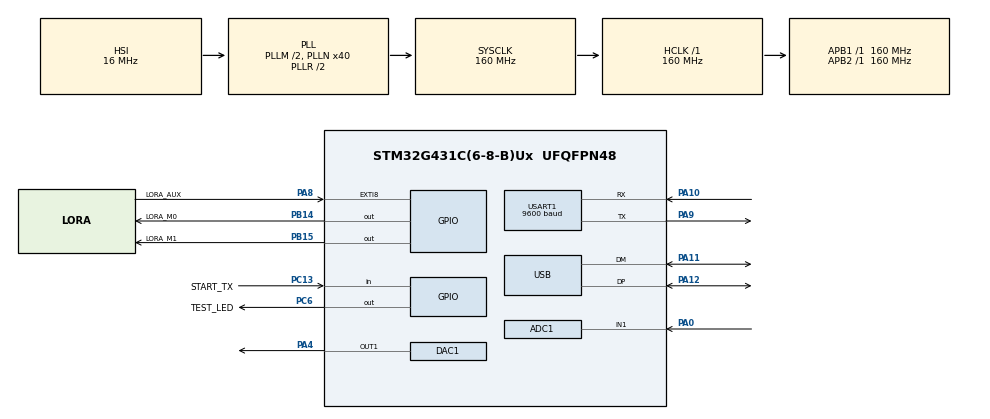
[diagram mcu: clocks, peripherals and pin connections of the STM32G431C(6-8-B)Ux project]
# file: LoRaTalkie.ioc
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ADC1.Channel-0\#ChannelRegularConversion=ADC_CHANNEL_1
ADC1.ClockPrescaler=ADC_CLOCK_SYNC_PCLK_DIV4
ADC1.ContinuousConvMode=DISABLE
ADC1.DMAContinuousRequests=ENABLE
ADC1.ExternalTrigConv=ADC_EXTERNALTRIG_T2_TRGO
ADC1.NbrOfConversionFlag=1
ADC1.OffsetNumber-0\#ChannelRegularConversion=ADC_OFFSET_NONE
ADC1.Overrun=ADC_OVR_DATA_OVERWRITTEN
ADC1.Rank-0\#ChannelRegularConversion=1
ADC1.Resolution=ADC_RESOLUTION_8B
ADC1.SamplingTime-0\#ChannelRegularConversion=ADC_SAMPLETIME_2CYCLES_5
ADC1.master=1
DAC1.DAC_Trigger_OUT1-DAC_OUT1=DAC_TRIGGER_T2_TRGO
DAC1.WaveGeneration_OUT1-DAC_OUT1=DISABLE
Dma.ADC1.0.Direction=DMA_PERIPH_TO_MEMORY
Dma.ADC1.0.EventEnable=DISABLE
Dma.ADC1.0.Instance=DMA1_Channel1
Dma.ADC1.0.MemDataAlignment=DMA_MDATAALIGN_HALFWORD
Dma.ADC1.0.MemInc=DMA_MINC_ENABLE
Dma.ADC1.0.Mode=DMA_CIRCULAR
Dma.ADC1.0.PeriphDataAlignment=DMA_PDATAALIGN_HALFWORD
Dma.ADC1.0.PeriphInc=DMA_PINC_DISABLE
Dma.ADC1.0.Polarity=HAL_DMAMUX_REQ_GEN_RISING
Dma.ADC1.0.Priority=DMA_PRIORITY_LOW
Dma.ADC1.0.RequestNumber=1
Dma.ADC1.0.SignalID=NONE
Dma.ADC1.0.SyncEnable=DISABLE
Dma.ADC1.0.SyncPolarity=HAL_DMAMUX_SYNC_NO_EVENT
Dma.ADC1.0.SyncRequestNumber=1
Dma.ADC1.0.SyncSignalID=NONE
Dma.DAC1_CH1.1.Direction=DMA_MEMORY_TO_PERIPH
Dma.DAC1_CH1.1.EventEnable=DISABLE
Dma.DAC1_CH1.1.Instance=DMA1_Channel2
Dma.DAC1_CH1.1.MemDataAlignment=DMA_MDATAALIGN_HALFWORD
Dma.DAC1_CH1.1.MemInc=DMA_MINC_ENABLE
Dma.DAC1_CH1.1.Mode=DMA_CIRCULAR
Dma.DAC1_CH1.1.PeriphDataAlignment=DMA_PDATAALIGN_WORD
Dma.DAC1_CH1.1.PeriphInc=DMA_PINC_DISABLE
Dma.DAC1_CH1.1.Polarity=HAL_DMAMUX_REQ_GEN_RISING
Dma.DAC1_CH1.1.Priority=DMA_PRIORITY_LOW
Dma.DAC1_CH1.1.RequestNumber=1
Dma.DAC1_CH1.1.SignalID=NONE
Dma.DAC1_CH1.1.SyncEnable=DISABLE
Dma.DAC1_CH1.1.SyncPolarity=HAL_DMAMUX_SYNC_NO_EVENT
Dma.DAC1_CH1.1.SyncRequestNumber=1
Dma.DAC1_CH1.1.SyncSignalID=NONE
Dma.Request0=ADC1
Dma.Request1=DAC1_CH1
Dma.Request2=USART1_RX
Dma.Request3=USART1_TX
Dma.USART1_RX.2.Direction=DMA_PERIPH_TO_MEMORY
Dma.USART1_RX.2.EventEnable=DISABLE
Dma.USART1_RX.2.Instance=DMA1_Channel3
Dma.USART1_RX.2.MemDataAlignment=DMA_MDATAALIGN_BYTE
Dma.USART1_RX.2.MemInc=DMA_MINC_ENABLE
Dma.USART1_RX.2.Mode=DMA_CIRCULAR
Dma.USART1_RX.2.PeriphDataAlignment=DMA_PDATAALIGN_BYTE
Dma.USART1_RX.2.PeriphInc=DMA_PINC_DISABLE
Dma.USART1_RX.2.Polarity=HAL_DMAMUX_REQ_GEN_RISING
Dma.USART1_RX.2.Priority=DMA_PRIORITY_LOW
Dma.USART1_RX.2.RequestNumber=1
Dma.USART1_RX.2.SignalID=NONE
Dma.USART1_RX.2.SyncEnable=DISABLE
Dma.USART1_RX.2.SyncPolarity=HAL_DMAMUX_SYNC_NO_EVENT
Dma.USART1_RX.2.SyncRequestNumber=1
Dma.USART1_RX.2.SyncSignalID=NONE
Dma.USART1_TX.3.Direction=DMA_MEMORY_TO_PERIPH
Dma.USART1_TX.3.EventEnable=DISABLE
Dma.USART1_TX.3.Instance=DMA1_Channel4
Dma.USART1_TX.3.MemDataAlignment=DMA_MDATAALIGN_BYTE
Dma.USART1_TX.3.MemInc=DMA_MINC_ENABLE
Dma.USART1_TX.3.Mode=DMA_NORMAL
Dma.USART1_TX.3.PeriphDataAlignment=DMA_PDATAALIGN_BYTE
Dma.USART1_TX.3.PeriphInc=DMA_PINC_DISABLE
Dma.USART1_TX.3.Polarity=HAL_DMAMUX_REQ_GEN_RISING
Dma.USART1_TX.3.Priority=DMA_PRIORITY_LOW
Dma.USART1_TX.3.RequestNumber=1
Dma.USART1_TX.3.SignalID=NONE
Dma.USART1_TX.3.SyncEnable=DISABLE
Dma.USART1_TX.3.SyncPolarity=HAL_DMAMUX_SYNC_NO_EVENT
Dma.USART1_TX.3.SyncRequestNumber=1
Dma.USART1_TX.3.SyncSignalID=NONE
Mcu.Family=STM32G4
Mcu.Name=STM32G431C(6-8-B)Ux
Mcu.Package=UFQFPN48
NVIC.DMA1_Channel1_IRQn=true\:0\:0\:false\:false\:true\:false\:true\:true
NVIC.DMA1_Channel2_IRQn=true\:0\:0\:false\:false\:true\:false\:true\:true
NVIC.DMA1_Channel3_IRQn=true\:0\:0\:false\:false\:true\:false\:true\:true
NVIC.DMA1_Channel4_IRQn=true\:0\:0\:false\:false\:true\:false\:true\:true
NVIC.EXTI9_5_IRQn=true\:0\:0\:false\:false\:true\:true\:true\:true
NVIC.PriorityGroup=NVIC_PRIORITYGROUP_4
NVIC.USART1_IRQn=true\:0\:0\:false\:false\:true\:true\:true\:true
NVIC.USB_LP_IRQn=true\:0\:0\:false\:false\:true\:false\:true\:true
PA0.Mode=IN1-Single-Ended
PA0.Signal=ADC1_IN1
PA10.Mode=Asynchronous
PA10.Signal=USART1_RX
PA11.Mode=Device
PA11.Signal=USB_DM
PA12.Mode=Device
PA12.Signal=USB_DP
PA4.Signal=COMP_DAC11_group
PA8.GPIO_Label=LORA_AUX
PA8.GPIO_ModeDefaultEXTI=GPIO_MODE_IT_RISING
PA8.Signal=GPXTI8
PA9.Mode=Asynchronous
PA9.Signal=USART1_TX
PB14.GPIO_Label=LORA_M0
PB14.Signal=GPIO_Output
PB15.GPIO_Label=LORA_M1
PB15.Signal=GPIO_Output
PC13.GPIO_Label=START_TX
PC13.GPIO_PuPd=GPIO_PULLDOWN
PC13.Signal=GPIO_Input
PC6.GPIO_Label=TEST_LED
PC6.Signal=GPIO_Output
PF0-OSC_IN.Mode=HSE-External-Oscillator
PF0-OSC_IN.Signal=RCC_OSC_IN
PF1-OSC_OUT.Mode=HSE-External-Oscillator
PF1-OSC_OUT.Signal=RCC_OSC_OUT
ProjectManager.HeapSize=0x200
ProjectManager.StackSize=0x400
ProjectManager.TargetToolchain=STM32CubeIDE
RCC.ADC12Freq_Value=160000000
RCC.AHBFreq_Value=160000000
RCC.APB1Freq_Value=160000000
RCC.APB1TimFreq_Value=160000000
RCC.APB2Freq_Value=160000000
RCC.APB2TimFreq_Value=160000000
RCC.CK48CLockSelection=RCC_USBCLKSOURCE_HSI48
RCC.CortexFreq_Value=160000000
RCC.EXTERNAL_CLOCK_VALUE=12288000
RCC.HCLKFreq_Value=160000000
RCC.HSE_VALUE=8000000
RCC.HSI48_VALUE=48000000
RCC.HSI_VALUE=16000000
RCC.LSE_VALUE=32768
RCC.PLLM=RCC_PLLM_DIV2
RCC.PLLN=40
RCC.SYSCLKFreq_VALUE=160000000
RCC.SYSCLKSource=RCC_SYSCLKSOURCE_PLLCLK
RCC.USBFreq_Value=48000000
RCC.VCOOutputFreq_Value=320000000
SH.COMP_DAC11_group.0=DAC1_OUT1,DAC_OUT1
TIM2.PeriodNoDither=49999
TIM2.TIM_MasterOutputTrigger=TIM_TRGO_UPDATE
USART1.BaudRate=9600
USART1.OverrunDisableParam=ADVFEATURE_OVERRUN_DISABLE
USART1.VirtualMode-Asynchronous=VM_ASYNC
USB_DEVICE.CLASS_NAME_FS=CDC
USB_DEVICE.VirtualMode=Cdc
USB_DEVICE.VirtualModeFS=Cdc_FS
VP_SYS_VS_DBSignals.Mode=DisableDeadBatterySignals
VP_TIM2_VS_ClockSourceINT.Mode=Internal
VP_USB_DEVICE_VS_USB_DEVICE_CDC_FS.Mode=CDC_FS
board=custom

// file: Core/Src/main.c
/* USER CODE BEGIN Header */
/**
  ******************************************************************************
  * @file           : main.c
  * @brief          : Main program body
  ******************************************************************************
  * @attention
  *
  * Copyright (c) 2025 STMicroelectronics.
  * All rights reserved.
  *
  * This software is licensed under terms that can be found in the LICENSE file
  * in the root directory of this software component.
  * If no LICENSE file comes with this software, it is provided AS-IS.
  *
  ******************************************************************************
  */
/* USER CODE END Header */
#include "main.h"
#include "usb_device.h"

/* USER CODE BEGIN Includes */
#include "CCalls.h"
/* USER CODE END Includes */

ADC_HandleTypeDef hadc1;
DMA_HandleTypeDef hdma_adc1;

DAC_HandleTypeDef hdac1;
DMA_HandleTypeDef hdma_dac1_ch1;

TIM_HandleTypeDef htim2;

UART_HandleTypeDef huart1;
DMA_HandleTypeDef hdma_usart1_rx;
DMA_HandleTypeDef hdma_usart1_tx;

void SystemClock_Config(void);
static void MX_GPIO_Init(void);
static void MX_DMA_Init(void);
static void MX_ADC1_Init(void);
static void MX_TIM2_Init(void);
static void MX_DAC1_Init(void);
static void MX_USART1_UART_Init(void);

int main(void)
{

  /* MCU Configuration--------------------------------------------------------*/

  /* Reset of all peripherals, Initializes the Flash interface and the Systick. */
  HAL_Init();

  /* Configure the system clock */
  SystemClock_Config();

  /* USER CODE BEGIN SysInit */
  createMainMCU(&huart1, &hdma_usart1_rx, &hdma_usart1_tx,
                &hadc1, &hdma_adc1, &hdac1,
                &hdma_dac1_ch1, &htim2);
  /* USER CODE END SysInit */

  /* Initialize all configured peripherals */
  MX_GPIO_Init();
  MX_DMA_Init();
  MX_ADC1_Init();
  MX_TIM2_Init();
  MX_DAC1_Init();
  MX_USART1_UART_Init();
  MX_USB_Device_Init();
  /* USER CODE BEGIN 2 */
  initMainMCU();
  /* USER CODE END 2 */

  /* Infinite loop */
  while (1)
  {

    /* USER CODE BEGIN 3 */
    loopMainMCU();
  }
  /* USER CODE END 3 */
}

void SystemClock_Config(void)
{
  RCC_OscInitTypeDef RCC_OscInitStruct = {0};
  RCC_ClkInitTypeDef RCC_ClkInitStruct = {0};

  /** Configure the main internal regulator output voltage
  */
  HAL_PWREx_ControlVoltageScaling(PWR_REGULATOR_VOLTAGE_SCALE1_BOOST);

  /** Initializes the RCC Oscillators according to the specified parameters
  * in the RCC_OscInitTypeDef structure.
  */
  RCC_OscInitStruct.OscillatorType = RCC_OSCILLATORTYPE_HSI|RCC_OSCILLATORTYPE_HSI48;
  RCC_OscInitStruct.HSIState = RCC_HSI_ON;
  RCC_OscInitStruct.HSICalibrationValue = RCC_HSICALIBRATION_DEFAULT;
  RCC_OscInitStruct.HSI48State = RCC_HSI48_ON;
  RCC_OscInitStruct.PLL.PLLState = RCC_PLL_ON;
  RCC_OscInitStruct.PLL.PLLSource = RCC_PLLSOURCE_HSI;
  RCC_OscInitStruct.PLL.PLLM = RCC_PLLM_DIV2;
  RCC_OscInitStruct.PLL.PLLN = 40;
  RCC_OscInitStruct.PLL.PLLP = RCC_PLLP_DIV2;
  RCC_OscInitStruct.PLL.PLLQ = RCC_PLLQ_DIV2;
  RCC_OscInitStruct.PLL.PLLR = RCC_PLLR_DIV2;
  if (HAL_RCC_OscConfig(&RCC_OscInitStruct) != HAL_OK)
  {
    Error_Handler();
  }

  /** Initializes the CPU, AHB and APB buses clocks
  */
  RCC_ClkInitStruct.ClockType = RCC_CLOCKTYPE_HCLK|RCC_CLOCKTYPE_SYSCLK
                              |RCC_CLOCKTYPE_PCLK1|RCC_CLOCKTYPE_PCLK2;
  RCC_ClkInitStruct.SYSCLKSource = RCC_SYSCLKSOURCE_PLLCLK;
  RCC_ClkInitStruct.AHBCLKDivider = RCC_SYSCLK_DIV1;
  RCC_ClkInitStruct.APB1CLKDivider = RCC_HCLK_DIV1;
  RCC_ClkInitStruct.APB2CLKDivider = RCC_HCLK_DIV1;

  if (HAL_RCC_ClockConfig(&RCC_ClkInitStruct, FLASH_LATENCY_4) != HAL_OK)
  {
    Error_Handler();
  }
}

static void MX_ADC1_Init(void)
{

  ADC_MultiModeTypeDef multimode = {0};
  ADC_ChannelConfTypeDef sConfig = {0};

  /** Common config
  */
  hadc1.Instance = ADC1;
  hadc1.Init.ClockPrescaler = ADC_CLOCK_SYNC_PCLK_DIV4;
  hadc1.Init.Resolution = ADC_RESOLUTION_8B;
  hadc1.Init.DataAlign = ADC_DATAALIGN_RIGHT;
  hadc1.Init.GainCompensation = 0;
  hadc1.Init.ScanConvMode = ADC_SCAN_DISABLE;
  hadc1.Init.EOCSelection = ADC_EOC_SINGLE_CONV;
  hadc1.Init.LowPowerAutoWait = DISABLE;
  hadc1.Init.ContinuousConvMode = DISABLE;
  hadc1.Init.NbrOfConversion = 1;
  hadc1.Init.DiscontinuousConvMode = DISABLE;
  hadc1.Init.ExternalTrigConv = ADC_EXTERNALTRIG_T2_TRGO;
  hadc1.Init.ExternalTrigConvEdge = ADC_EXTERNALTRIGCONVEDGE_RISING;
  hadc1.Init.DMAContinuousRequests = ENABLE;
  hadc1.Init.Overrun = ADC_OVR_DATA_OVERWRITTEN;
  hadc1.Init.OversamplingMode = DISABLE;
  if (HAL_ADC_Init(&hadc1) != HAL_OK)
  {
    Error_Handler();
  }

  /** Configure the ADC multi-mode
  */
  multimode.Mode = ADC_MODE_INDEPENDENT;
  if (HAL_ADCEx_MultiModeConfigChannel(&hadc1, &multimode) != HAL_OK)
  {
    Error_Handler();
  }

  /** Configure Regular Channel
  */
  sConfig.Channel = ADC_CHANNEL_1;
  sConfig.Rank = ADC_REGULAR_RANK_1;
  sConfig.SamplingTime = ADC_SAMPLETIME_2CYCLES_5;
  sConfig.SingleDiff = ADC_SINGLE_ENDED;
  sConfig.OffsetNumber = ADC_OFFSET_NONE;
  sConfig.Offset = 0;
  if (HAL_ADC_ConfigChannel(&hadc1, &sConfig) != HAL_OK)
  {
    Error_Handler();
  }

}

static void MX_DAC1_Init(void)
{

  DAC_ChannelConfTypeDef sConfig = {0};

  /** DAC Initialization
  */
  hdac1.Instance = DAC1;
  if (HAL_DAC_Init(&hdac1) != HAL_OK)
  {
    Error_Handler();
  }

  /** DAC channel OUT1 config
  */
  sConfig.DAC_HighFrequency = DAC_HIGH_FREQUENCY_INTERFACE_MODE_AUTOMATIC;
  sConfig.DAC_DMADoubleDataMode = DISABLE;
  sConfig.DAC_SignedFormat = DISABLE;
  sConfig.DAC_SampleAndHold = DAC_SAMPLEANDHOLD_DISABLE;
  sConfig.DAC_Trigger = DAC_TRIGGER_T2_TRGO;
  sConfig.DAC_Trigger2 = DAC_TRIGGER_NONE;
  sConfig.DAC_OutputBuffer = DAC_OUTPUTBUFFER_ENABLE;
  sConfig.DAC_ConnectOnChipPeripheral = DAC_CHIPCONNECT_EXTERNAL;
  sConfig.DAC_UserTrimming = DAC_TRIMMING_FACTORY;
  if (HAL_DAC_ConfigChannel(&hdac1, &sConfig, DAC_CHANNEL_1) != HAL_OK)
  {
    Error_Handler();
  }

}

static void MX_TIM2_Init(void)
{

  TIM_ClockConfigTypeDef sClockSourceConfig = {0};
  TIM_MasterConfigTypeDef sMasterConfig = {0};

  htim2.Instance = TIM2;
  htim2.Init.Prescaler = 0;
  htim2.Init.CounterMode = TIM_COUNTERMODE_UP;
  htim2.Init.Period = 49999;
  htim2.Init.ClockDivision = TIM_CLOCKDIVISION_DIV1;
  htim2.Init.AutoReloadPreload = TIM_AUTORELOAD_PRELOAD_DISABLE;
  if (HAL_TIM_Base_Init(&htim2) != HAL_OK)
  {
    Error_Handler();
  }
  sClockSourceConfig.ClockSource = TIM_CLOCKSOURCE_INTERNAL;
  if (HAL_TIM_ConfigClockSource(&htim2, &sClockSourceConfig) != HAL_OK)
  {
    Error_Handler();
  }
  sMasterConfig.MasterOutputTrigger = TIM_TRGO_UPDATE;
  sMasterConfig.MasterSlaveMode = TIM_MASTERSLAVEMODE_DISABLE;
  if (HAL_TIMEx_MasterConfigSynchronization(&htim2, &sMasterConfig) != HAL_OK)
  {
    Error_Handler();
  }

}

static void MX_USART1_UART_Init(void)
{

  huart1.Instance = USART1;
  huart1.Init.BaudRate = 9600;
  huart1.Init.WordLength = UART_WORDLENGTH_8B;
  huart1.Init.StopBits = UART_STOPBITS_1;
  huart1.Init.Parity = UART_PARITY_NONE;
  huart1.Init.Mode = UART_MODE_TX_RX;
  huart1.Init.HwFlowCtl = UART_HWCONTROL_NONE;
  huart1.Init.OverSampling = UART_OVERSAMPLING_16;
  huart1.Init.OneBitSampling = UART_ONE_BIT_SAMPLE_DISABLE;
  huart1.Init.ClockPrescaler = UART_PRESCALER_DIV1;
  huart1.AdvancedInit.AdvFeatureInit = UART_ADVFEATURE_RXOVERRUNDISABLE_INIT;
  huart1.AdvancedInit.OverrunDisable = UART_ADVFEATURE_OVERRUN_DISABLE;
  if (HAL_UART_Init(&huart1) != HAL_OK)
  {
    Error_Handler();
  }
  if (HAL_UARTEx_SetTxFifoThreshold(&huart1, UART_TXFIFO_THRESHOLD_1_8) != HAL_OK)
  {
    Error_Handler();
  }
  if (HAL_UARTEx_SetRxFifoThreshold(&huart1, UART_RXFIFO_THRESHOLD_1_8) != HAL_OK)
  {
    Error_Handler();
  }
  if (HAL_UARTEx_DisableFifoMode(&huart1) != HAL_OK)
  {
    Error_Handler();
  }

}

static void MX_DMA_Init(void)
{

  /* DMA controller clock enable */
  __HAL_RCC_DMAMUX1_CLK_ENABLE();
  __HAL_RCC_DMA1_CLK_ENABLE();

  /* DMA interrupt init */
  /* DMA1_Channel1_IRQn interrupt configuration */
  HAL_NVIC_SetPriority(DMA1_Channel1_IRQn, 0, 0);
  HAL_NVIC_EnableIRQ(DMA1_Channel1_IRQn);
  /* DMA1_Channel2_IRQn interrupt configuration */
  HAL_NVIC_SetPriority(DMA1_Channel2_IRQn, 0, 0);
  HAL_NVIC_EnableIRQ(DMA1_Channel2_IRQn);
  /* DMA1_Channel3_IRQn interrupt configuration */
  HAL_NVIC_SetPriority(DMA1_Channel3_IRQn, 0, 0);
  HAL_NVIC_EnableIRQ(DMA1_Channel3_IRQn);
  /* DMA1_Channel4_IRQn interrupt configuration */
  HAL_NVIC_SetPriority(DMA1_Channel4_IRQn, 0, 0);
  HAL_NVIC_EnableIRQ(DMA1_Channel4_IRQn);

}

static void MX_GPIO_Init(void)
{
  GPIO_InitTypeDef GPIO_InitStruct = {0};

  /* GPIO Ports Clock Enable */
  __HAL_RCC_GPIOC_CLK_ENABLE();
  __HAL_RCC_GPIOF_CLK_ENABLE();
  __HAL_RCC_GPIOA_CLK_ENABLE();
  __HAL_RCC_GPIOB_CLK_ENABLE();

  /*Configure GPIO pin Output Level */
  HAL_GPIO_WritePin(GPIOB, LORA_M0_Pin|LORA_M1_Pin, GPIO_PIN_RESET);

  /*Configure GPIO pin Output Level */
  HAL_GPIO_WritePin(TEST_LED_GPIO_Port, TEST_LED_Pin, GPIO_PIN_RESET);

  /*Configure GPIO pin : START_TX_Pin */
  GPIO_InitStruct.Pin = START_TX_Pin;
  GPIO_InitStruct.Mode = GPIO_MODE_INPUT;
  GPIO_InitStruct.Pull = GPIO_PULLDOWN;
  HAL_GPIO_Init(START_TX_GPIO_Port, &GPIO_InitStruct);

  /*Configure GPIO pins : LORA_M0_Pin LORA_M1_Pin */
  GPIO_InitStruct.Pin = LORA_M0_Pin|LORA_M1_Pin;
  GPIO_InitStruct.Mode = GPIO_MODE_OUTPUT_PP;
  GPIO_InitStruct.Pull = GPIO_NOPULL;
  GPIO_InitStruct.Speed = GPIO_SPEED_FREQ_LOW;
  HAL_GPIO_Init(GPIOB, &GPIO_InitStruct);

  /*Configure GPIO pin : TEST_LED_Pin */
  GPIO_InitStruct.Pin = TEST_LED_Pin;
  GPIO_InitStruct.Mode = GPIO_MODE_OUTPUT_PP;
  GPIO_InitStruct.Pull = GPIO_NOPULL;
  GPIO_InitStruct.Speed = GPIO_SPEED_FREQ_LOW;
  HAL_GPIO_Init(TEST_LED_GPIO_Port, &GPIO_InitStruct);

  /*Configure GPIO pin : LORA_AUX_Pin */
  GPIO_InitStruct.Pin = LORA_AUX_Pin;
  GPIO_InitStruct.Mode = GPIO_MODE_IT_RISING;
  GPIO_InitStruct.Pull = GPIO_NOPULL;
  HAL_GPIO_Init(LORA_AUX_GPIO_Port, &GPIO_InitStruct);

  /* EXTI interrupt init*/
  HAL_NVIC_SetPriority(EXTI9_5_IRQn, 0, 0);
  HAL_NVIC_EnableIRQ(EXTI9_5_IRQn);

}

void Error_Handler(void)
{
  /* USER CODE BEGIN Error_Handler_Debug */
  /* User can add his own implementation to report the HAL error return state */
  __disable_irq();
  while (1)
  {
    HAL_GPIO_WritePin(TEST_LED_GPIO_Port, TEST_LED_Pin, GPIO_PIN_SET);
    for(uint32_t i = 0; i < 3200000; i++){ __NOP(); }
    HAL_GPIO_WritePin(TEST_LED_GPIO_Port, TEST_LED_Pin, GPIO_PIN_RESET);
    for(uint32_t i = 0; i < 3200000; i++){ __NOP(); }
  }
  /* USER CODE END Error_Handler_Debug */
}
